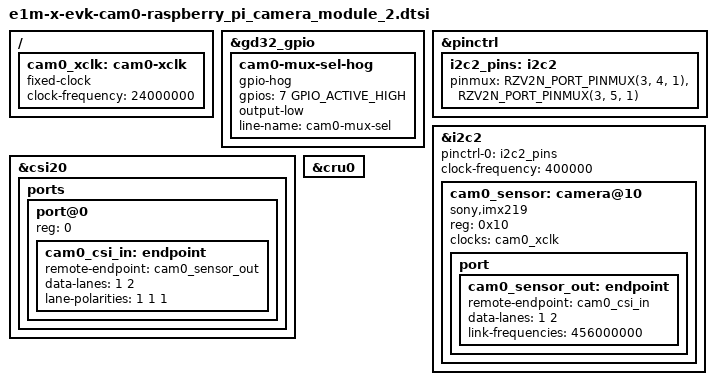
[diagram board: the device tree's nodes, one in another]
// SPDX-License-Identifier: (GPL-2.0-only OR BSD-2-Clause)
/*
 * GENERATED by scripts/gen_camera_dt.py -- DO NOT EDIT BY HAND.
 * Raspberry Pi Camera Module 2 (IMX219, 2-lane CSI-2) on e1m-x-evk CAM0 (J5):
 * E1M_X_CSI0 -> &csi20 -> &cru0 -> /dev/video*.
 * Inputs: metadata/camera_modules/raspberry_pi_camera_module_2.yaml, metadata/chips/imx219.yaml,
 * metadata/boards/e1m-x-evk.yaml camera_connectors.CAM0, SoM pad_routes, SoC linux_dt.
 * Regenerate: python3 scripts/gen_camera_dt.py
 */

/ {
	cam0_xclk: cam0-xclk {
		compatible = "fixed-clock";
		#clock-cells = <0>;
		clock-frequency = <24000000>;
	};
};

&gd32_gpio {
	/* XEVK_PIN_CAM0_MUX_SEL = line 7: raw level LOW routes J5. */
	cam0-mux-sel-hog {
		gpio-hog;
		gpios = <7 GPIO_ACTIVE_HIGH>;
		output-low;
		line-name = "cam0-mux-sel";
	};
};

/* XEVK_PIN_CAM0_EN: not routed to a Linux GPIO controller, not modelled. */
/* XEVK_PIN_CAM0_RST: not routed to a Linux GPIO controller, not modelled. */

&pinctrl {
	/* XEVK_I2C_BUS_DSI_CSI0 = RIIC2 */
	i2c2_pins: i2c2 {
		pinmux = <RZV2N_PORT_PINMUX(3, 4, 1)>, /* I2C2_SDA */
			 <RZV2N_PORT_PINMUX(3, 5, 1)>; /* I2C2_SCL */
	};
};

&i2c2 {
	pinctrl-0 = <&i2c2_pins>;
	pinctrl-names = "default";
	clock-frequency = <400000>;
	status = "okay";

	cam0_sensor: camera@10 {
		compatible = "sony,imx219";
		reg = <0x10>;
		clocks = <&cam0_xclk>;

		port {
			cam0_sensor_out: endpoint {
				remote-endpoint = <&cam0_csi_in>;
				data-lanes = <1 2>;
				link-frequencies = /bits/ 64 <456000000>;
			};
		};
	};
};

&csi20 {
	status = "okay";

	ports {
		#address-cells = <1>;
		#size-cells = <0>;

		port@0 {
			reg = <0>;
			cam0_csi_in: endpoint {
				remote-endpoint = <&cam0_sensor_out>;
				data-lanes = <1 2>;
				/* camera_connectors.CAM0.lane_polarity (clock first). */
				lane-polarities = <1 1 1>;
			};
		};
	};
};

&cru0 {
	status = "okay";
};
